VERSION "1.0"

NS_ :

BS_:

BU_: ACM_A ACM_B RCM

BA_DEF_ BO_ "GenMsgCycleTime" INT 0 10000;
BA_DEF_ BO_ "GenMsgSendType" ENUM "Cyclic","Event","CyclicAndEvent","IfActive","NoMsgSendType";
BA_DEF_ BO_ "GenMsgILSupport" ENUM "No","Yes";
BA_DEF_ BO_ "CANFD_BRS" ENUM "0","1";
BA_DEF_ BO_ "VFrameFormat" ENUM "StandardCAN","ExtendedCAN","reserved","reserved","reserved","reserved","reserved","reserved","reserved","reserved","reserved","reserved","reserved","reserved","StandardCAN_FD","ExtendedCAN_FD";
BA_DEF_ SG_ "GenSigStartValue" INT 0 4294967295;
BA_DEF_  "DBName" STRING ;
BA_DEF_  "BusType" STRING ;
BA_DEF_DEF_ "GenMsgCycleTime" 0;
BA_DEF_DEF_ "GenMsgSendType" "Cyclic";
BA_DEF_DEF_ "GenMsgILSupport" "No";
BA_DEF_DEF_ "CANFD_BRS" "1";
BA_DEF_DEF_ "VFrameFormat" "StandardCAN_FD";
BA_DEF_DEF_ "GenSigStartValue" 0;
BA_DEF_DEF_ "DBName" "demo";
BA_DEF_DEF_ "BusType" "CAN FD";

CM_ "Synthetic matrix generated by tools/gen_demo_dbc.py. All entities are fictional.";

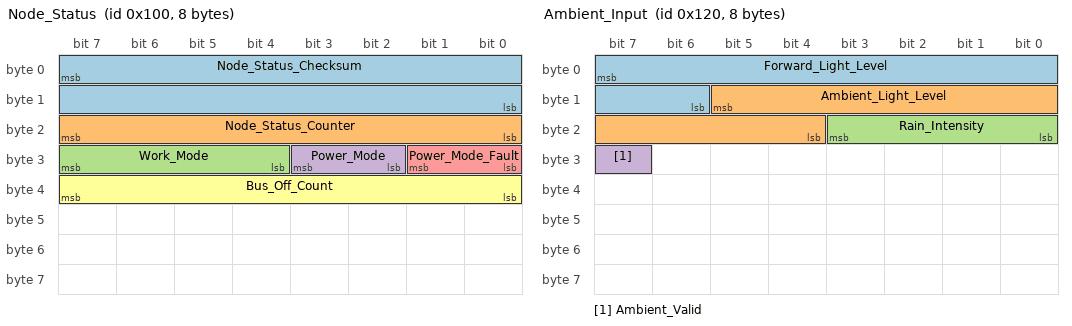
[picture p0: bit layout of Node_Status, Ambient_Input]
BO_ 256 Node_Status: 8 Vector__XXX
 SG_ Node_Status_Checksum : 7|16@0+ (1,0) [|] ""  Vector__XXX
 SG_ Node_Status_Counter : 23|8@0+ (1,0) [|] ""  Vector__XXX
 SG_ Work_Mode : 31|4@0+ (1,0) [|] ""  Vector__XXX
 SG_ Power_Mode : 27|2@0+ (1,0) [|] ""  Vector__XXX
 SG_ Power_Mode_Fault : 25|2@0+ (1,0) [|] ""  Vector__XXX
 SG_ Bus_Off_Count : 39|8@0+ (1,0) [|255] ""  Vector__XXX

BO_ 272 Vehicle_Motion: 32 Vector__XXX
 SG_ Motion_Checksum : 7|16@0+ (1,0) [|] ""  Vector__XXX
 SG_ Motion_Counter : 23|8@0+ (1,0) [|] ""  Vector__XXX
 SG_ Vehicle_Speed : 31|13@0+ (0.05625,0) [0|460.74] "km/h"  Vector__XXX
 SG_ Vehicle_Speed_Valid : 34|1@0+ (1,0) [|] ""  Vector__XXX
 SG_ Steering_Angle : 33|14@0+ (0.1,-780) [-780|858.3] "deg"  Vector__XXX
 SG_ Steering_Rate : 51|15@0+ (0.1,-1024) [-1024|2253] "deg/s"  Vector__XXX
 SG_ Yaw_Rate : 68|15@0+ (0.01,-163.84) [-163.84|163.83] "deg/s"  Vector__XXX
 SG_ Lateral_Accel : 85|10@0+ (0.01,-5.12) [-5.12|5.11] "m/s2"  Vector__XXX

BO_ 288 Ambient_Input: 8 Vector__XXX
 SG_ Forward_Light_Level : 7|10@0+ (10,0) [|10230] "lx"  Vector__XXX
 SG_ Ambient_Light_Level : 13|10@0+ (10,0) [|10230] "lx"  Vector__XXX
 SG_ Rain_Intensity : 19|4@0+ (1,0) [|] ""  Vector__XXX
 SG_ Ambient_Valid : 31|1@0+ (1,0) [|] ""  Vector__XXX

BO_ 304 Control_Cmd: 32 Vector__XXX
 SG_ Cmd_Checksum : 7|16@0+ (1,0) [|] ""  Vector__XXX
 SG_ Cmd_Counter : 23|8@0+ (1,0) [|] ""  Vector__XXX
 SG_ Position_Lamp_On : 31|2@0+ (1,0) [|] ""  Vector__XXX
 SG_ Position_Lamp_Brightness : 29|3@0+ (1,0) [|] ""  Vector__XXX
 SG_ Turn_Lamp_On : 26|2@0+ (1,0) [|] ""  Vector__XXX
 SG_ Turn_Lamp_Brightness : 24|7@0+ (1,0) [|100] "%"  Vector__XXX
 SG_ Low_Beam_On : 33|2@0+ (1,0) [|] ""  Vector__XXX
 SG_ High_Beam_On : 47|2@0+ (1,0) [|] ""  Vector__XXX
 SG_ Adaptive_Light_Enable : 45|2@0+ (1,0) [|] ""  Vector__XXX
 SG_ Projection_Scene : 43|4@0+ (1,0) [|] ""  Vector__XXX
 SG_ Projection_Intensity : 55|8@0+ (1,0) [|100] "%"  Vector__XXX
 SG_ Aux_Lamp_On : 63|2@0+ (1,0) [|] ""  Vector__XXX

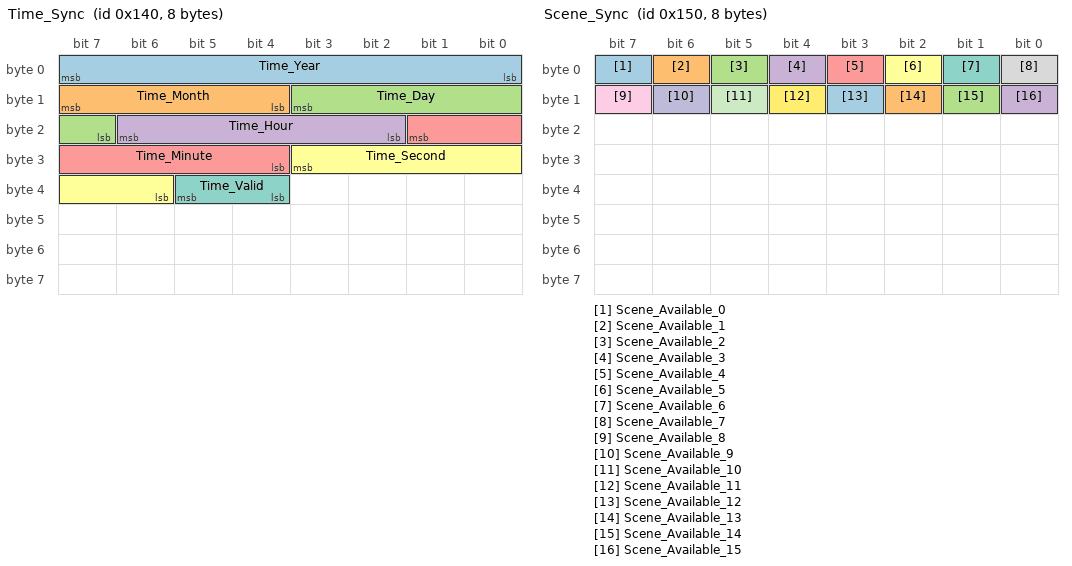
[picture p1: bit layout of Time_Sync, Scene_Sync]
BO_ 320 Time_Sync: 8 Vector__XXX
 SG_ Time_Year : 7|8@0+ (1,2000) [2000|2255] "year"  Vector__XXX
 SG_ Time_Month : 15|4@0+ (1,0) [1|12] "month"  Vector__XXX
 SG_ Time_Day : 11|5@0+ (1,0) [1|31] "day"  Vector__XXX
 SG_ Time_Hour : 22|5@0+ (1,0) [|23] "h"  Vector__XXX
 SG_ Time_Minute : 17|6@0+ (1,0) [|59] "min"  Vector__XXX
 SG_ Time_Second : 27|6@0+ (1,0) [|59] "s"  Vector__XXX
 SG_ Time_Valid : 37|2@0+ (1,0) [|] ""  Vector__XXX

BO_ 336 Scene_Sync: 8 Vector__XXX
 SG_ Scene_Available_0 : 7|1@0+ (1,0) [|] ""  Vector__XXX
 SG_ Scene_Available_1 : 6|1@0+ (1,0) [|] ""  Vector__XXX
 SG_ Scene_Available_2 : 5|1@0+ (1,0) [|] ""  Vector__XXX
 SG_ Scene_Available_3 : 4|1@0+ (1,0) [|] ""  Vector__XXX
 SG_ Scene_Available_4 : 3|1@0+ (1,0) [|] ""  Vector__XXX
 SG_ Scene_Available_5 : 2|1@0+ (1,0) [|] ""  Vector__XXX
 SG_ Scene_Available_6 : 1|1@0+ (1,0) [|] ""  Vector__XXX
 SG_ Scene_Available_7 : 0|1@0+ (1,0) [|] ""  Vector__XXX
 SG_ Scene_Available_8 : 15|1@0+ (1,0) [|] ""  Vector__XXX
 SG_ Scene_Available_9 : 14|1@0+ (1,0) [|] ""  Vector__XXX
 SG_ Scene_Available_10 : 13|1@0+ (1,0) [|] ""  Vector__XXX
 SG_ Scene_Available_11 : 12|1@0+ (1,0) [|] ""  Vector__XXX
 SG_ Scene_Available_12 : 11|1@0+ (1,0) [|] ""  Vector__XXX
 SG_ Scene_Available_13 : 10|1@0+ (1,0) [|] ""  Vector__XXX
 SG_ Scene_Available_14 : 9|1@0+ (1,0) [|] ""  Vector__XXX
 SG_ Scene_Available_15 : 8|1@0+ (1,0) [|] ""  Vector__XXX

BO_ 352 Sensor_Fusion: 32 Vector__XXX
 SG_ Fusion_Checksum : 7|16@0+ (1,0) [|] ""  Vector__XXX
 SG_ Fusion_Counter : 23|8@0+ (1,0) [|] ""  Vector__XXX
 SG_ Object_Count : 31|6@0+ (1,0) [|63] ""  Vector__XXX
 SG_ Nearest_Object_Distance : 25|12@0+ (0.05,0) [|204.75] "m"  Vector__XXX
 SG_ Nearest_Object_Speed : 45|12@0+ (0.05,-102.4) [-102.4|102.35] "m/s"  Vector__XXX
 SG_ Fusion_Valid : 49|1@0+ (1,0) [|] ""  Vector__XXX

BO_ 512 ACM_A_Status: 32 ACM_A
 SG_ ACM_A_Checksum : 7|16@0+ (1,0) [|] ""  Vector__XXX
 SG_ ACM_A_Counter : 23|8@0+ (1,0) [|] ""  Vector__XXX
 SG_ ACM_A_Position_Lamp_State : 31|2@0+ (1,0) [|] ""  Vector__XXX
 SG_ ACM_A_Position_Lamp_Brightness : 29|3@0+ (1,0) [|100] "%"  Vector__XXX
 SG_ ACM_A_Position_Lamp_Fault : 26|2@0+ (1,0) [|] ""  Vector__XXX
 SG_ ACM_A_Turn_Lamp_State : 24|2@0+ (1,0) [|] ""  Vector__XXX
 SG_ ACM_A_Turn_Lamp_Fault : 38|2@0+ (1,0) [|] ""  Vector__XXX
 SG_ ACM_A_Low_Beam_State : 36|2@0+ (1,0) [|] ""  Vector__XXX
 SG_ ACM_A_High_Beam_State : 34|2@0+ (1,0) [|] ""  Vector__XXX
 SG_ ACM_A_Adaptive_Light_State : 32|2@0+ (1,0) [|] ""  Vector__XXX
 SG_ ACM_A_Adaptive_Light_Fault : 46|2@0+ (1,0) [|] ""  Vector__XXX
 SG_ ACM_A_Supply_Voltage : 44|8@0+ (0.1,0) [|25.5] "V"  Vector__XXX
 SG_ ACM_A_Temperature : 52|8@0+ (0.5,-40) [-40|87.5] "degC"  Vector__XXX
 SG_ ACM_A_Projection_State : 60|4@0+ (1,0) [|] ""  Vector__XXX
 SG_ ACM_A_Projection_Intensity : 56|8@0+ (1,0) [|100] "%"  Vector__XXX
 SG_ ACM_A_Projection_Fault : 64|2@0+ (1,0) [|] ""  Vector__XXX

BO_ 513 ACM_B_Status: 32 ACM_B
 SG_ ACM_B_Checksum : 7|16@0+ (1,0) [|] ""  Vector__XXX
 SG_ ACM_B_Counter : 23|8@0+ (1,0) [|] ""  Vector__XXX
 SG_ ACM_B_Position_Lamp_State : 31|2@0+ (1,0) [|] ""  Vector__XXX
 SG_ ACM_B_Position_Lamp_Brightness : 29|3@0+ (1,0) [|100] "%"  Vector__XXX
 SG_ ACM_B_Position_Lamp_Fault : 26|2@0+ (1,0) [|] ""  Vector__XXX
 SG_ ACM_B_Turn_Lamp_State : 24|2@0+ (1,0) [|] ""  Vector__XXX
 SG_ ACM_B_Turn_Lamp_Fault : 38|2@0+ (1,0) [|] ""  Vector__XXX
 SG_ ACM_B_Low_Beam_State : 36|2@0+ (1,0) [|] ""  Vector__XXX
 SG_ ACM_B_High_Beam_State : 34|2@0+ (1,0) [|] ""  Vector__XXX
 SG_ ACM_B_Adaptive_Light_State : 32|2@0+ (1,0) [|] ""  Vector__XXX
 SG_ ACM_B_Adaptive_Light_Fault : 46|2@0+ (1,0) [|] ""  Vector__XXX
 SG_ ACM_B_Supply_Voltage : 44|8@0+ (0.1,0) [|25.5] "V"  Vector__XXX
 SG_ ACM_B_Temperature : 52|8@0+ (0.5,-40) [-40|87.5] "degC"  Vector__XXX
 SG_ ACM_B_Projection_State : 60|4@0+ (1,0) [|] ""  Vector__XXX
 SG_ ACM_B_Projection_Intensity : 56|8@0+ (1,0) [|100] "%"  Vector__XXX
 SG_ ACM_B_Projection_Fault : 64|2@0+ (1,0) [|] ""  Vector__XXX

BO_ 768 ACM_A_Diagnostics: 32 ACM_A
 SG_ ACM_A_Total_Fault_Count : 7|8@0+ (1,0) [|255] ""  Vector__XXX
 SG_ ACM_A_Frame_Index : 15|5@0+ (1,0) [|31] ""  Vector__XXX
 SG_ ACM_A_Supplier_Code : 10|3@0+ (1,0) [|7] ""  Vector__XXX
 SG_ ACM_A_Fault_Code_1 : 23|12@0+ (1,0) [|4095] ""  Vector__XXX
 SG_ ACM_A_Fault_Code_2 : 27|12@0+ (1,0) [|4095] ""  Vector__XXX
 SG_ ACM_A_Fault_Code_3 : 47|12@0+ (1,0) [|4095] ""  Vector__XXX
 SG_ ACM_A_Fault_Code_4 : 51|12@0+ (1,0) [|4095] ""  Vector__XXX
 SG_ ACM_A_Fault_Code_5 : 71|12@0+ (1,0) [|4095] ""  Vector__XXX

BO_ 769 ACM_B_Diagnostics: 32 ACM_B
 SG_ ACM_B_Total_Fault_Count : 7|8@0+ (1,0) [|255] ""  Vector__XXX
 SG_ ACM_B_Frame_Index : 15|5@0+ (1,0) [|31] ""  Vector__XXX
 SG_ ACM_B_Supplier_Code : 10|3@0+ (1,0) [|7] ""  Vector__XXX
 SG_ ACM_B_Fault_Code_1 : 23|12@0+ (1,0) [|4095] ""  Vector__XXX
 SG_ ACM_B_Fault_Code_2 : 27|12@0+ (1,0) [|4095] ""  Vector__XXX
 SG_ ACM_B_Fault_Code_3 : 47|12@0+ (1,0) [|4095] ""  Vector__XXX
 SG_ ACM_B_Fault_Code_4 : 51|12@0+ (1,0) [|4095] ""  Vector__XXX
 SG_ ACM_B_Fault_Code_5 : 71|12@0+ (1,0) [|4095] ""  Vector__XXX

BO_ 1024 Calibration_Block: 64 RCM
 SG_ Calibration_Byte_1 : 7|8@0+ (1,0) [|255] ""  Vector__XXX
 SG_ Calibration_Byte_2 : 15|8@0+ (1,0) [|255] ""  Vector__XXX
 SG_ Calibration_Byte_3 : 23|8@0+ (1,0) [|255] ""  Vector__XXX
 SG_ Calibration_Byte_4 : 31|8@0+ (1,0) [|255] ""  Vector__XXX
 SG_ Calibration_Byte_5 : 39|8@0+ (1,0) [|255] ""  Vector__XXX
 SG_ Calibration_Byte_6 : 47|8@0+ (1,0) [|255] ""  Vector__XXX
 SG_ Calibration_Byte_7 : 55|8@0+ (1,0) [|255] ""  Vector__XXX
 SG_ Calibration_Byte_8 : 63|8@0+ (1,0) [|255] ""  Vector__XXX
 SG_ Calibration_Byte_9 : 71|8@0+ (1,0) [|255] ""  Vector__XXX
 SG_ Calibration_Byte_10 : 79|8@0+ (1,0) [|255] ""  Vector__XXX
 SG_ Calibration_Byte_11 : 87|8@0+ (1,0) [|255] ""  Vector__XXX
 SG_ Calibration_Byte_12 : 95|8@0+ (1,0) [|255] ""  Vector__XXX
 SG_ Calibration_Byte_13 : 103|8@0+ (1,0) [|255] ""  Vector__XXX
 SG_ Calibration_Byte_14 : 111|8@0+ (1,0) [|255] ""  Vector__XXX
 SG_ Calibration_Byte_15 : 119|8@0+ (1,0) [|255] ""  Vector__XXX
 SG_ Calibration_Byte_16 : 127|8@0+ (1,0) [|255] ""  Vector__XXX
 SG_ Calibration_Byte_17 : 135|8@0+ (1,0) [|255] ""  Vector__XXX
 SG_ Calibration_Byte_18 : 143|8@0+ (1,0) [|255] ""  Vector__XXX
 SG_ Calibration_Byte_19 : 151|8@0+ (1,0) [|255] ""  Vector__XXX
 SG_ Calibration_Byte_20 : 159|8@0+ (1,0) [|255] ""  Vector__XXX
 SG_ Calibration_Byte_21 : 167|8@0+ (1,0) [|255] ""  Vector__XXX
 SG_ Calibration_Byte_22 : 175|8@0+ (1,0) [|255] ""  Vector__XXX
 SG_ Calibration_Byte_23 : 183|8@0+ (1,0) [|255] ""  Vector__XXX
 SG_ Calibration_Byte_24 : 191|8@0+ (1,0) [|255] ""  Vector__XXX
 SG_ Calibration_Byte_25 : 199|8@0+ (1,0) [|255] ""  Vector__XXX
 SG_ Calibration_Byte_26 : 207|8@0+ (1,0) [|255] ""  Vector__XXX
 SG_ Calibration_Byte_27 : 215|8@0+ (1,0) [|255] ""  Vector__XXX
 SG_ Calibration_Byte_28 : 223|8@0+ (1,0) [|255] ""  Vector__XXX
 SG_ Calibration_Byte_29 : 231|8@0+ (1,0) [|255] ""  Vector__XXX
 SG_ Calibration_Byte_30 : 239|8@0+ (1,0) [|255] ""  Vector__XXX
 SG_ Calibration_Byte_31 : 247|8@0+ (1,0) [|255] ""  Vector__XXX
 SG_ Calibration_Byte_32 : 255|8@0+ (1,0) [|255] ""  Vector__XXX

BO_ 1280 Log_Snapshot: 64 ACM_A
 SG_ Log_Word_1 : 7|32@0+ (1,0) [|4294967295] ""  Vector__XXX
 SG_ Log_Word_2 : 39|32@0+ (1,0) [|4294967295] ""  Vector__XXX
 SG_ Log_Word_3 : 71|32@0+ (1,0) [|4294967295] ""  Vector__XXX
 SG_ Log_Word_4 : 103|32@0+ (1,0) [|4294967295] ""  Vector__XXX

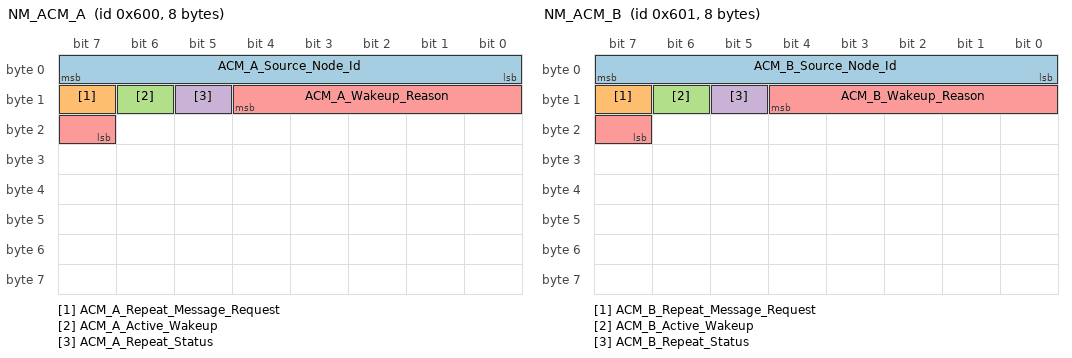
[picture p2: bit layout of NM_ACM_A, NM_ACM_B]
BO_ 1536 NM_ACM_A: 8 ACM_A
 SG_ ACM_A_Source_Node_Id : 7|8@0+ (1,0) [|255] ""  Vector__XXX
 SG_ ACM_A_Repeat_Message_Request : 15|1@0+ (1,0) [|] ""  Vector__XXX
 SG_ ACM_A_Active_Wakeup : 14|1@0+ (1,0) [|] ""  Vector__XXX
 SG_ ACM_A_Repeat_Status : 13|1@0+ (1,0) [|] ""  Vector__XXX
 SG_ ACM_A_Wakeup_Reason : 12|6@0+ (1,0) [|63] ""  Vector__XXX

BO_ 1537 NM_ACM_B: 8 ACM_B
 SG_ ACM_B_Source_Node_Id : 7|8@0+ (1,0) [|255] ""  Vector__XXX
 SG_ ACM_B_Repeat_Message_Request : 15|1@0+ (1,0) [|] ""  Vector__XXX
 SG_ ACM_B_Active_Wakeup : 14|1@0+ (1,0) [|] ""  Vector__XXX
 SG_ ACM_B_Repeat_Status : 13|1@0+ (1,0) [|] ""  Vector__XXX
 SG_ ACM_B_Wakeup_Reason : 12|6@0+ (1,0) [|63] ""  Vector__XXX

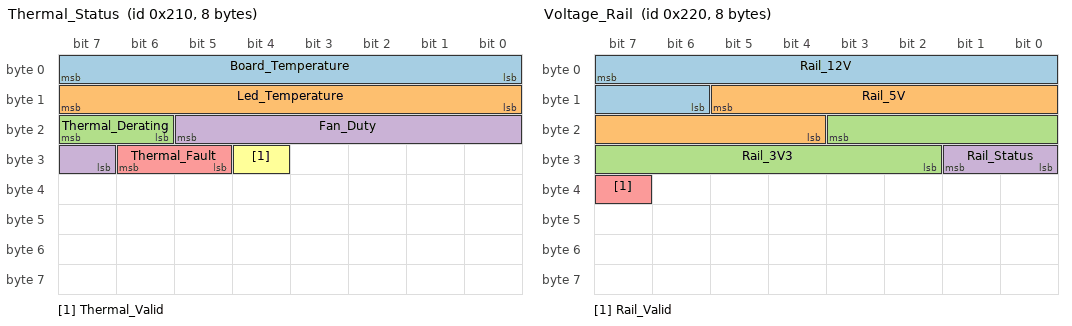
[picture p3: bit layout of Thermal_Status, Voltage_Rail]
BO_ 528 Thermal_Status: 8 ACM_A
 SG_ Board_Temperature : 7|8@0+ (0.5,-40) [-40|87.5] "degC"  Vector__XXX
 SG_ Led_Temperature : 15|8@0+ (0.5,-40) [-40|87.5] "degC"  Vector__XXX
 SG_ Thermal_Derating : 23|2@0+ (1,0) [|] ""  Vector__XXX
 SG_ Fan_Duty : 21|7@0+ (1,0) [|100] "%"  Vector__XXX
 SG_ Thermal_Fault : 30|2@0+ (1,0) [|] ""  Vector__XXX
 SG_ Thermal_Valid : 28|1@0+ (1,0) [|] ""  Vector__XXX

BO_ 544 Voltage_Rail: 8 ACM_B
 SG_ Rail_12V : 7|10@0+ (0.01,0) [|10.23] "V"  Vector__XXX
 SG_ Rail_5V : 13|10@0+ (0.005,0) [|5.115] "V"  Vector__XXX
 SG_ Rail_3V3 : 19|10@0+ (0.005,0) [|5.115] "V"  Vector__XXX
 SG_ Rail_Status : 25|2@0+ (1,0) [|] ""  Vector__XXX
 SG_ Rail_Valid : 39|1@0+ (1,0) [|] ""  Vector__XXX

BO_ 2015 Diag_Functional: 64 Vector__XXX
 SG_ Diag_Functional_Data : 7|64@0+ (1,0) [|18446744073709551615] ""  Vector__XXX

BO_ 1792 Diag_Phys_ACM_A: 64 Vector__XXX
 SG_ Diag_Phys_A_Data : 7|64@0+ (1,0) [|18446744073709551615] ""  Vector__XXX

BO_ 1800 Diag_Resp_ACM_A: 64 ACM_A
 SG_ Diag_Resp_A_Data : 7|64@0+ (1,0) [|18446744073709551615] ""  Vector__XXX

VAL_ 256 Work_Mode 0 "Init" 1 "Idle" 2 "Active" 3 "Degraded" 15 "Invalid" ;
VAL_ 256 Power_Mode 0 "Off" 1 "On" 2 "Reserved" 3 "Invalid" ;
VAL_ 256 Power_Mode_Fault 0 "False" 1 "True" 2 "Reserved" 3 "Invalid" ;
VAL_ 272 Vehicle_Speed_Valid 0 "Invalid" 1 "Valid" ;
VAL_ 288 Rain_Intensity 0 "None" 1 "Light" 2 "Medium" 3 "Heavy" 15 "Invalid" ;
VAL_ 288 Ambient_Valid 0 "Invalid" 1 "Valid" ;
VAL_ 304 Position_Lamp_On 0 "Init" 1 "Off" 2 "On" 3 "Invalid" ;
VAL_ 304 Position_Lamp_Brightness 0 "Initial" 1 "Night" 2 "Day1" 3 "Day2" 7 "Invalid" ;
VAL_ 304 Turn_Lamp_On 0 "Init" 1 "Off" 2 "On" 3 "Invalid" ;
VAL_ 304 Low_Beam_On 0 "Init" 1 "Off" 2 "On" 3 "Invalid" ;
VAL_ 304 High_Beam_On 0 "Init" 1 "Off" 2 "On" 3 "Invalid" ;
VAL_ 304 Adaptive_Light_Enable 0 "Init" 1 "Disabled" 2 "Enabled" 3 "Invalid" ;
VAL_ 304 Projection_Scene 0 "None" 1 "Welcome" 2 "Goodbye" 3 "Charging" 15 "Invalid" ;
VAL_ 304 Aux_Lamp_On 0 "Init" 1 "Off" 2 "On" 3 "Invalid" ;
VAL_ 320 Time_Valid 0 "Invalid" 1 "Valid" 2 "Reserved" 3 "Invalid" ;
VAL_ 336 Scene_Available_0 0 "NotAvailable" 1 "Available" ;
VAL_ 336 Scene_Available_1 0 "NotAvailable" 1 "Available" ;
VAL_ 336 Scene_Available_2 0 "NotAvailable" 1 "Available" ;
VAL_ 336 Scene_Available_3 0 "NotAvailable" 1 "Available" ;
VAL_ 336 Scene_Available_4 0 "NotAvailable" 1 "Available" ;
VAL_ 336 Scene_Available_5 0 "NotAvailable" 1 "Available" ;
VAL_ 336 Scene_Available_6 0 "NotAvailable" 1 "Available" ;
VAL_ 336 Scene_Available_7 0 "NotAvailable" 1 "Available" ;
VAL_ 336 Scene_Available_8 0 "NotAvailable" 1 "Available" ;
VAL_ 336 Scene_Available_9 0 "NotAvailable" 1 "Available" ;
VAL_ 336 Scene_Available_10 0 "NotAvailable" 1 "Available" ;
VAL_ 336 Scene_Available_11 0 "NotAvailable" 1 "Available" ;
VAL_ 336 Scene_Available_12 0 "NotAvailable" 1 "Available" ;
VAL_ 336 Scene_Available_13 0 "NotAvailable" 1 "Available" ;
VAL_ 336 Scene_Available_14 0 "NotAvailable" 1 "Available" ;
VAL_ 336 Scene_Available_15 0 "NotAvailable" 1 "Available" ;
VAL_ 352 Fusion_Valid 0 "Invalid" 1 "Valid" ;
VAL_ 512 ACM_A_Position_Lamp_State 0 "Init" 1 "Off" 2 "On" 3 "Invalid" ;
VAL_ 512 ACM_A_Position_Lamp_Fault 0 "NoFault" 1 "Fault" 2 "Reserved" 3 "Invalid" ;
VAL_ 512 ACM_A_Turn_Lamp_State 0 "Init" 1 "Off" 2 "On" 3 "Invalid" ;
VAL_ 512 ACM_A_Turn_Lamp_Fault 0 "NoFault" 1 "Fault" 2 "Reserved" 3 "Invalid" ;
VAL_ 512 ACM_A_Low_Beam_State 0 "Init" 1 "Off" 2 "On" 3 "Invalid" ;
VAL_ 512 ACM_A_High_Beam_State 0 "Init" 1 "Off" 2 "On" 3 "Invalid" ;
VAL_ 512 ACM_A_Adaptive_Light_State 0 "Init" 1 "Off" 2 "On" 3 "Invalid" ;
VAL_ 512 ACM_A_Adaptive_Light_Fault 0 "NoFault" 1 "Fault" 2 "Reserved" 3 "Invalid" ;
VAL_ 512 ACM_A_Projection_State 0 "Off" 1 "Standby" 2 "Projecting" 3 "Fault" 15 "Invalid" ;
VAL_ 512 ACM_A_Projection_Fault 0 "NoFault" 1 "Fault" 2 "Reserved" 3 "Invalid" ;
VAL_ 513 ACM_B_Position_Lamp_State 0 "Init" 1 "Off" 2 "On" 3 "Invalid" ;
VAL_ 513 ACM_B_Position_Lamp_Fault 0 "NoFault" 1 "Fault" 2 "Reserved" 3 "Invalid" ;
VAL_ 513 ACM_B_Turn_Lamp_State 0 "Init" 1 "Off" 2 "On" 3 "Invalid" ;
VAL_ 513 ACM_B_Turn_Lamp_Fault 0 "NoFault" 1 "Fault" 2 "Reserved" 3 "Invalid" ;
VAL_ 513 ACM_B_Low_Beam_State 0 "Init" 1 "Off" 2 "On" 3 "Invalid" ;
VAL_ 513 ACM_B_High_Beam_State 0 "Init" 1 "Off" 2 "On" 3 "Invalid" ;
VAL_ 513 ACM_B_Adaptive_Light_State 0 "Init" 1 "Off" 2 "On" 3 "Invalid" ;
VAL_ 513 ACM_B_Adaptive_Light_Fault 0 "NoFault" 1 "Fault" 2 "Reserved" 3 "Invalid" ;
VAL_ 513 ACM_B_Projection_State 0 "Off" 1 "Standby" 2 "Projecting" 3 "Fault" 15 "Invalid" ;
VAL_ 513 ACM_B_Projection_Fault 0 "NoFault" 1 "Fault" 2 "Reserved" 3 "Invalid" ;
VAL_ 768 ACM_A_Supplier_Code 0 "Unspecified" 1 "SupplierA" 2 "SupplierB" 7 "Invalid" ;
VAL_ 769 ACM_B_Supplier_Code 0 "Unspecified" 1 "SupplierA" 2 "SupplierB" 7 "Invalid" ;
VAL_ 1536 ACM_A_Repeat_Message_Request 0 "No" 1 "Yes" ;
VAL_ 1536 ACM_A_Active_Wakeup 0 "No" 1 "Yes" ;
VAL_ 1536 ACM_A_Repeat_Status 0 "No" 1 "Yes" ;
VAL_ 1536 ACM_A_Wakeup_Reason 0 "Undefined" 1 "PowerOn" 2 "Can" 3 "Local" 63 "Invalid" ;
VAL_ 1537 ACM_B_Repeat_Message_Request 0 "No" 1 "Yes" ;
VAL_ 1537 ACM_B_Active_Wakeup 0 "No" 1 "Yes" ;
VAL_ 1537 ACM_B_Repeat_Status 0 "No" 1 "Yes" ;
VAL_ 1537 ACM_B_Wakeup_Reason 0 "Undefined" 1 "PowerOn" 2 "Can" 3 "Local" 63 "Invalid" ;
VAL_ 528 Thermal_Derating 0 "None" 1 "Level1" 2 "Level2" 3 "Invalid" ;
VAL_ 528 Thermal_Fault 0 "NoFault" 1 "Fault" 2 "Reserved" 3 "Invalid" ;
VAL_ 528 Thermal_Valid 0 "Invalid" 1 "Valid" ;
VAL_ 544 Rail_Status 0 "Ok" 1 "UnderVoltage" 2 "OverVoltage" 3 "Invalid" ;
VAL_ 544 Rail_Valid 0 "Invalid" 1 "Valid" ;

CM_ BO_ 256 "primary node status heartbeat";
CM_ BO_ 272 "motion inputs from the chassis domain";
CM_ BO_ 288 "ambient light and rain sensing";
CM_ BO_ 304 "actuator commands toward both lamp modules";
CM_ BO_ 320 "wall clock broadcast";
CM_ BO_ 336 "bitmap of projection scenes available on this vehicle";
CM_ BO_ 512 "state feedback from ACM_A";
CM_ BO_ 513 "state feedback from ACM_B";
CM_ BO_ 768 "condensed fault snapshot from ACM_A";
CM_ BO_ 769 "condensed fault snapshot from ACM_B";
CM_ BO_ 1024 "calibration payload, transferred on request only";
CM_ BO_ 1280 "diagnostic log words, little structure by design";
CM_ BO_ 1536 "AUTOSAR network management frame";
CM_ BO_ 1537 "AUTOSAR network management frame";
CM_ BO_ 2015 "functional diagnostic request; payload length varies with the service";
CM_ SG_ 256 Node_Status_Checksum "CRC16 over bytes 2..7, data id 0x9A11";
CM_ SG_ 256 Node_Status_Counter "rolling counter 0..255";
CM_ SG_ 256 Work_Mode "node work mode";
CM_ SG_ 256 Power_Mode "supply mode as seen by the node";
CM_ SG_ 256 Bus_Off_Count "cumulative bus-off events since power-on";
CM_ SG_ 272 Steering_Angle "steering wheel angle, left positive";
CM_ SG_ 288 Forward_Light_Level "brightness ahead of the vehicle";

BA_ "GenMsgCycleTime" BO_ 256 20;
BA_ "GenMsgILSupport" BO_ 256 "Yes";
BA_ "VFrameFormat" BO_ 256 "StandardCAN";
BA_ "GenMsgCycleTime" BO_ 272 50;
BA_ "GenMsgILSupport" BO_ 272 "Yes";
BA_ "GenMsgCycleTime" BO_ 288 100;
BA_ "GenMsgILSupport" BO_ 288 "Yes";
BA_ "VFrameFormat" BO_ 288 "StandardCAN";
BA_ "GenMsgCycleTime" BO_ 304 100;
BA_ "GenMsgSendType" BO_ 304 "CyclicAndEvent";
BA_ "GenMsgILSupport" BO_ 304 "Yes";
BA_ "GenMsgCycleTime" BO_ 320 1000;
BA_ "GenMsgILSupport" BO_ 320 "Yes";
BA_ "VFrameFormat" BO_ 320 "StandardCAN";
BA_ "GenMsgCycleTime" BO_ 336 50;
BA_ "GenMsgILSupport" BO_ 336 "Yes";
BA_ "VFrameFormat" BO_ 336 "StandardCAN";
BA_ "GenMsgCycleTime" BO_ 352 50;
BA_ "GenMsgILSupport" BO_ 352 "Yes";
BA_ "GenMsgCycleTime" BO_ 512 100;
BA_ "GenMsgILSupport" BO_ 512 "Yes";
BA_ "GenMsgCycleTime" BO_ 513 100;
BA_ "GenMsgILSupport" BO_ 513 "Yes";
BA_ "GenMsgCycleTime" BO_ 768 500;
BA_ "GenMsgILSupport" BO_ 768 "Yes";
BA_ "GenMsgCycleTime" BO_ 769 500;
BA_ "GenMsgILSupport" BO_ 769 "Yes";
BA_ "GenMsgSendType" BO_ 1024 "Event";
BA_ "GenMsgILSupport" BO_ 1024 "Yes";
BA_ "GenMsgSendType" BO_ 1280 "Event";
BA_ "GenMsgILSupport" BO_ 1280 "Yes";
BA_ "GenMsgSendType" BO_ 1536 "Event";
BA_ "GenMsgILSupport" BO_ 1536 "Yes";
BA_ "VFrameFormat" BO_ 1536 "StandardCAN";
BA_ "GenMsgSendType" BO_ 1537 "Event";
BA_ "GenMsgILSupport" BO_ 1537 "Yes";
BA_ "VFrameFormat" BO_ 1537 "StandardCAN";
BA_ "GenMsgCycleTime" BO_ 528 500;
BA_ "GenMsgILSupport" BO_ 528 "Yes";
BA_ "VFrameFormat" BO_ 528 "StandardCAN";
BA_ "GenMsgCycleTime" BO_ 544 500;
BA_ "GenMsgILSupport" BO_ 544 "Yes";
BA_ "VFrameFormat" BO_ 544 "StandardCAN";
BA_ "GenMsgSendType" BO_ 2015 "Event";
BA_ "GenMsgILSupport" BO_ 2015 "Yes";
BA_ "GenMsgSendType" BO_ 1792 "Event";
BA_ "GenMsgILSupport" BO_ 1792 "Yes";
BA_ "GenMsgSendType" BO_ 1800 "Event";
BA_ "GenMsgILSupport" BO_ 1800 "Yes";
